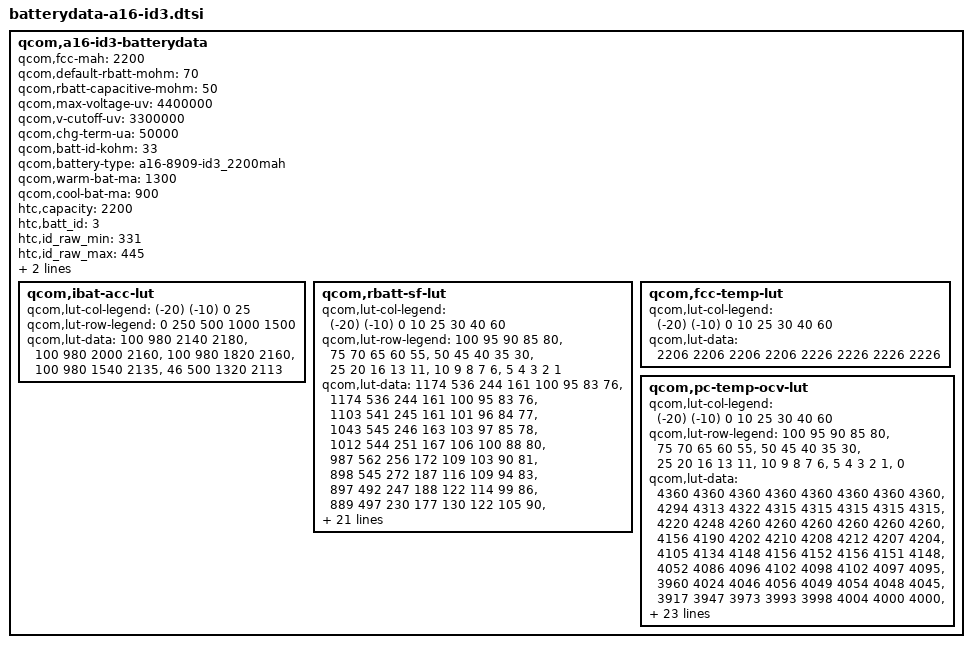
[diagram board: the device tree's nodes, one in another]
/* Copyright (c) 2013, The Linux Foundation. All rights reserved.
 *
 * This program is free software; you can redistribute it and/or modify
 * it under the terms of the GNU General Public License version 2 and
 * only version 2 as published by the Free Software Foundation.
 *
 * This program is distributed in the hope that it will be useful,
 * but WITHOUT ANY WARRANTY; without even the implied warranty of
 * MERCHANTABILITY or FITNESS FOR A PARTICULAR PURPOSE.  See the
 * GNU General Public License for more details.
 */

qcom,a16-id3-batterydata {
	qcom,fcc-mah = <2200>;
	qcom,default-rbatt-mohm = <70>;
	qcom,rbatt-capacitive-mohm = <50>;
	qcom,max-voltage-uv = <4400000>;
	qcom,v-cutoff-uv = <3300000>;
	qcom,chg-term-ua = <50000>;
	qcom,batt-id-kohm = <33>;
	qcom,battery-type = "a16-8909-id3_2200mah";
	qcom,warm-bat-ma = <1300>;
	qcom,cool-bat-ma = <900>;
	htc,capacity = <2200>;
	htc,batt_id = <3>;
	htc,id_raw_min = <331>;
	htc,id_raw_max = <445>;
	htc,type = <1>;
	htc,model_name = "B0PKX100";

	qcom,ibat-acc-lut {
		qcom,lut-col-legend = <(-20) (-10) 0 25>;
		qcom,lut-row-legend = <0 250 500 1000 1500>;
		qcom,lut-data = <100 980 2140 2180>,
				<100 980 2000 2160>,
				<100 980 1820 2160>,
				<100 980 1540 2135>,
				<46 500 1320 2113>;
	};

	qcom,rbatt-sf-lut {
		qcom,lut-col-legend = <(-20) (-10) 0 10 25 30 40 60>;
		qcom,lut-row-legend = <100 95 90 85 80>,
					<75 70 65 60 55>,
					<50 45 40 35 30>,
					<25 20 16 13 11>,
					<10 9 8 7 6>,
					<5 4 3 2 1>;
		qcom,lut-data = <1174 536 244 161 100 95 83 76>,
				<1174 536 244 161 100 95 83 76>,
				<1103 541 245 161 101 96 84 77>,
				<1043 545 246 163 103 97 85 78>,
				<1012 544 251 167 106 100 88 80>,
				<987 562 256 172 109 103 90 81>,
				<898 545 272 187 116 109 94 83>,
				<897 492 247 188 122 114 99 86>,
				<889 497 230 177 130 122 105 90>,
				<899 494 223 156 107 100 91 82>,
				<920 493 221 152 99 95 84 78>,
				<945 511 222 153 100 96 85 78>,
				<978 536 226 155 102 99 87 80>,
				<1014 565 232 158 106 102 91 84>,
				<1061 598 244 162 107 103 92 85>,
				<1121 637 260 168 103 97 86 79>,
				<1196 677 275 170 101 97 84 78>,
				<1275 725 286 174 103 97 86 78>,
				<1333 781 296 176 103 97 85 78>,
				<1278 804 290 176 100 96 83 76>,
				<1321 788 297 173 101 97 84 78>,
				<1370 816 307 177 103 98 87 79>,
				<1426 850 326 182 106 100 88 82>,
				<1497 892 344 190 109 104 91 86>,
				<1665 937 366 200 113 107 95 87>,
				<1943 986 388 204 111 105 90 82>,
				<2357 1043 402 203 108 102 89 80>,
				<2993 1126 444 216 111 104 90 83>,
				<4021 1329 511 236 116 111 97 88>,
				<6863 2495 694 309 154 151 134 107>;
	};

	qcom,fcc-temp-lut {
		qcom,lut-col-legend = <(-20) (-10) 0 10 25 30 40 60>;
		qcom,lut-data = <2206 2206 2206 2206 2226 2226 2226 2226>;
	};

	qcom,pc-temp-ocv-lut {
		qcom,lut-col-legend = <(-20) (-10) 0 10 25 30 40 60>;
		qcom,lut-row-legend = <100 95 90 85 80>,
					<75 70 65 60 55>,
					<50 45 40 35 30>,
					<25 20 16 13 11>,
					<10 9 8 7 6>,
					<5 4 3 2 1>,
					<0>;
		qcom,lut-data = <4360 4360 4360 4360 4360 4360 4360 4360>,
				<4294 4313 4322 4315 4315 4315 4315 4315>,
				<4220 4248 4260 4260 4260 4260 4260 4260>,
				<4156 4190 4202 4210 4208 4212 4207 4204>,
				<4105 4134 4148 4156 4152 4156 4151 4148>,
				<4052 4086 4096 4102 4098 4102 4097 4095>,
				<3960 4024 4046 4056 4049 4054 4048 4045>,
				<3917 3947 3973 3993 3998 4004 4000 4000>,
				<3874 3908 3926 3946 3956 3962 3958 3956>,
				<3844 3870 3886 3896 3900 3902 3902 3901>,
				<3824 3836 3854 3860 3862 3864 3864 3864>,
				<3806 3815 3826 3833 3834 3838 3836 3836>,
				<3790 3800 3805 3811 3814 3816 3814 3814>,
				<3775 3786 3789 3792 3794 3796 3796 3796>,
				<3760 3772 3777 3778 3778 3780 3778 3776>,
				<3744 3757 3765 3766 3761 3758 3754 3743>,
				<3729 3734 3748 3748 3740 3738 3732 3719>,
				<3716 3717 3726 3726 3720 3717 3712 3699>,
				<3705 3706 3707 3705 3700 3698 3692 3680>,
				<3696 3698 3698 3694 3690 3688 3682 3672>,
				<3690 3694 3694 3692 3688 3686 3682 3670>,
				<3682 3690 3692 3690 3688 3685 3680 3669>,
				<3673 3684 3689 3688 3686 3684 3680 3668>,
				<3662 3677 3686 3686 3684 3680 3676 3665>,
				<3646 3665 3680 3680 3678 3674 3670 3656>,
				<3621 3644 3664 3660 3658 3652 3645 3628>,
				<3586 3606 3624 3618 3614 3607 3599 3582>,
				<3538 3552 3566 3558 3555 3547 3540 3524>,
				<3466 3474 3487 3477 3474 3466 3459 3444>,
				<3350 3348 3366 3351 3356 3340 3337 3324>,
				<3000 3000 3000 3000 3000 3000 3000 3000>;
	};
};
